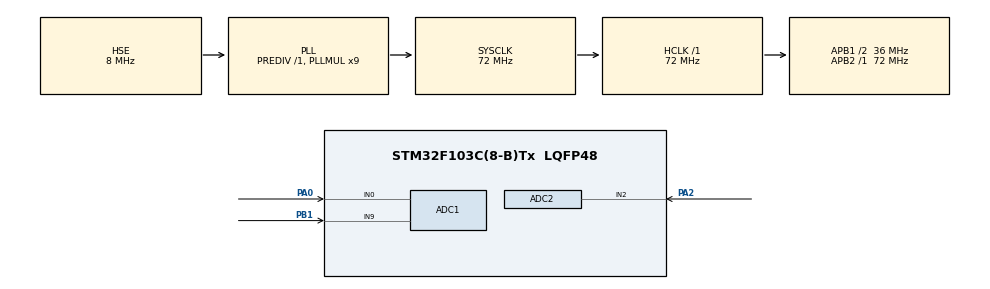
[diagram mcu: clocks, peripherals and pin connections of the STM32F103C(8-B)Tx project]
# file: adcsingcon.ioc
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ADC1.Channel-0\#ChannelRegularConversion=ADC_CHANNEL_0
ADC1.ContinuousConvMode=ENABLE
ADC1.NbrOfConversionFlag=1
ADC1.Rank-0\#ChannelRegularConversion=1
ADC1.SamplingTime-0\#ChannelRegularConversion=ADC_SAMPLETIME_1CYCLE_5
ADC1.master=1
ADC2.Channel-0\#ChannelRegularConversion=ADC_CHANNEL_2
ADC2.NbrOfConversionFlag=1
ADC2.Rank-0\#ChannelRegularConversion=1
ADC2.SamplingTime-0\#ChannelRegularConversion=ADC_SAMPLETIME_1CYCLE_5
Mcu.Family=STM32F1
Mcu.Name=STM32F103C(8-B)Tx
Mcu.Package=LQFP48
NVIC.PriorityGroup=NVIC_PRIORITYGROUP_4
PA0-WKUP.Signal=ADCx_IN0
PA13.Mode=Serial_Wire
PA13.Signal=SYS_JTMS-SWDIO
PA14.Mode=Serial_Wire
PA14.Signal=SYS_JTCK-SWCLK
PA2.Signal=ADCx_IN2
PB1.Signal=ADCx_IN9
PD0-OSC_IN.Mode=HSE-External-Oscillator
PD0-OSC_IN.Signal=RCC_OSC_IN
PD1-OSC_OUT.Mode=HSE-External-Oscillator
PD1-OSC_OUT.Signal=RCC_OSC_OUT
ProjectManager.HeapSize=0x200
ProjectManager.StackSize=0x400
ProjectManager.TargetToolchain=STM32CubeIDE
RCC.ADCPresc=RCC_ADCPCLK2_DIV6
RCC.AHBFreq_Value=72000000
RCC.APB1CLKDivider=RCC_HCLK_DIV2
RCC.APB1Freq_Value=36000000
RCC.APB1TimFreq_Value=72000000
RCC.APB2Freq_Value=72000000
RCC.APB2TimFreq_Value=72000000
RCC.HCLKFreq_Value=72000000
RCC.PLLMUL=RCC_PLL_MUL9
RCC.PLLSourceVirtual=RCC_PLLSOURCE_HSE
RCC.SYSCLKFreq_VALUE=72000000
RCC.SYSCLKSource=RCC_SYSCLKSOURCE_PLLCLK
RCC.USBFreq_Value=72000000
SH.ADCx_IN0.0=ADC1_IN0,IN0
SH.ADCx_IN2.0=ADC2_IN2,IN2
SH.ADCx_IN9.0=ADC1_IN9,IN9
board=custom

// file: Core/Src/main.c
/* USER CODE BEGIN Header */
/**
  ******************************************************************************
  * @file           : main.c
  * @brief          : Main program body
  ******************************************************************************
  * @attention
  *
  * STM32F103C8T6 - ADC1 (Continuous) dan ADC2 (Single Conversion)
  *
  ******************************************************************************
  */
/* USER CODE END Header */
#include "main.h"

ADC_HandleTypeDef hadc1;
ADC_HandleTypeDef hadc2;

/* USER CODE BEGIN PV */
volatile uint16_t adc1Value = 0;   // hasil ADC1 (continuous mode)
volatile uint16_t adc2Value = 0;   // hasil ADC2 (single mode)
/* USER CODE END PV */

void SystemClock_Config(void);
static void MX_GPIO_Init(void);
static void MX_ADC1_Init(void);
static void MX_ADC2_Init(void);

int main(void)
{
  /* MCU Configuration--------------------------------------------------------*/
  HAL_Init();
  SystemClock_Config();
  MX_GPIO_Init();
  MX_ADC1_Init();
  MX_ADC2_Init();

  /* USER CODE BEGIN 2 */
  // ==== Kalibrasi ADC wajib di STM32F1 ====
  HAL_ADCEx_Calibration_Start(&hadc1);
  HAL_ADCEx_Calibration_Start(&hadc2);

  // Start ADC1 di continuous mode
  HAL_ADC_Start(&hadc1);
  /* USER CODE END 2 */

  /* Infinite loop */
  while (1)
  {
    // ====== Baca ADC1 (continuous mode) ======
    if (HAL_ADC_PollForConversion(&hadc1, 10) == HAL_OK) {
      adc1Value = HAL_ADC_GetValue(&hadc1);
    }

    // ====== Baca ADC2 (single conversion mode) ======
    HAL_ADC_Start(&hadc2);
    if (HAL_ADC_PollForConversion(&hadc2, 10) == HAL_OK) {
      adc2Value = HAL_ADC_GetValue(&hadc2);
    }
    HAL_ADC_Stop(&hadc2);   // penting untuk single conversion

    HAL_Delay(200); // Delay agar tidak terlalu cepat
  }
}

void SystemClock_Config(void)
{
  RCC_OscInitTypeDef RCC_OscInitStruct = {0};
  RCC_ClkInitTypeDef RCC_ClkInitStruct = {0};
  RCC_PeriphCLKInitTypeDef PeriphClkInit = {0};

  RCC_OscInitStruct.OscillatorType = RCC_OSCILLATORTYPE_HSE;
  RCC_OscInitStruct.HSEState = RCC_HSE_ON;
  RCC_OscInitStruct.HSEPredivValue = RCC_HSE_PREDIV_DIV1;
  RCC_OscInitStruct.HSIState = RCC_HSI_ON;
  RCC_OscInitStruct.PLL.PLLState = RCC_PLL_ON;
  RCC_OscInitStruct.PLL.PLLSource = RCC_PLLSOURCE_HSE;
  RCC_OscInitStruct.PLL.PLLMUL = RCC_PLL_MUL9;
  if (HAL_RCC_OscConfig(&RCC_OscInitStruct) != HAL_OK) {
    Error_Handler();
  }

  RCC_ClkInitStruct.ClockType = RCC_CLOCKTYPE_HCLK|RCC_CLOCKTYPE_SYSCLK
                              |RCC_CLOCKTYPE_PCLK1|RCC_CLOCKTYPE_PCLK2;
  RCC_ClkInitStruct.SYSCLKSource = RCC_SYSCLKSOURCE_PLLCLK;
  RCC_ClkInitStruct.AHBCLKDivider = RCC_SYSCLK_DIV1;
  RCC_ClkInitStruct.APB1CLKDivider = RCC_HCLK_DIV2;
  RCC_ClkInitStruct.APB2CLKDivider = RCC_HCLK_DIV1;

  if (HAL_RCC_ClockConfig(&RCC_ClkInitStruct, FLASH_LATENCY_2) != HAL_OK) {
    Error_Handler();
  }

  // Clock ADC
  PeriphClkInit.PeriphClockSelection = RCC_PERIPHCLK_ADC;
  PeriphClkInit.AdcClockSelection = RCC_ADCPCLK2_DIV6;
  if (HAL_RCCEx_PeriphCLKConfig(&PeriphClkInit) != HAL_OK) {
    Error_Handler();
  }
}

static void MX_ADC1_Init(void)
{
  ADC_ChannelConfTypeDef sConfig = {0};

  hadc1.Instance = ADC1;
  hadc1.Init.ScanConvMode = ADC_SCAN_DISABLE;
  hadc1.Init.ContinuousConvMode = ENABLE;       // Continuous mode
  hadc1.Init.DiscontinuousConvMode = DISABLE;
  hadc1.Init.ExternalTrigConv = ADC_SOFTWARE_START;
  hadc1.Init.DataAlign = ADC_DATAALIGN_RIGHT;
  hadc1.Init.NbrOfConversion = 1;
  if (HAL_ADC_Init(&hadc1) != HAL_OK) {
    Error_Handler();
  }

  sConfig.Channel = ADC_CHANNEL_0;              // PA0 -> ADC1_IN0
  sConfig.Rank = ADC_REGULAR_RANK_1;
  sConfig.SamplingTime = ADC_SAMPLETIME_239CYCLES_5; // sampling panjang biar stabil
  if (HAL_ADC_ConfigChannel(&hadc1, &sConfig) != HAL_OK) {
    Error_Handler();
  }
}

static void MX_ADC2_Init(void)
{
  ADC_ChannelConfTypeDef sConfig = {0};

  hadc2.Instance = ADC2;
  hadc2.Init.ScanConvMode = ADC_SCAN_DISABLE;
  hadc2.Init.ContinuousConvMode = DISABLE;      // Single conversion mode
  hadc2.Init.DiscontinuousConvMode = DISABLE;
  hadc2.Init.ExternalTrigConv = ADC_SOFTWARE_START;
  hadc2.Init.DataAlign = ADC_DATAALIGN_RIGHT;
  hadc2.Init.NbrOfConversion = 1;
  if (HAL_ADC_Init(&hadc2) != HAL_OK) {
    Error_Handler();
  }

  sConfig.Channel = ADC_CHANNEL_2;              // PA2 -> ADC2_IN2
  sConfig.Rank = ADC_REGULAR_RANK_1;
  sConfig.SamplingTime = ADC_SAMPLETIME_239CYCLES_5;
  if (HAL_ADC_ConfigChannel(&hadc2, &sConfig) != HAL_OK) {
    Error_Handler();
  }
}

static void MX_GPIO_Init(void)
{
  __HAL_RCC_GPIOD_CLK_ENABLE();
  __HAL_RCC_GPIOA_CLK_ENABLE();
}

/**
  * @brief  Error Handler
  */
void Error_Handler(void)
{
  __disable_irq();
  while (1) { }
}
